# ABE_PRM register map
Vendor: Texas Instruments
Peripheral module from a debugger description file (folder omap4460).
Registers are 32-bit, access not given, reset 0x0 unless marked. A register's access mark holds for its fields unless they carry their own. Offsets are as the file gives them; lines under a group give offsets from that group; [hi:lo] are bit positions; {n}, {i} and the like mark numbered series; 'fields as' and 'values as' point back to an identical list; <NAME> marks a mode.

## ABE_PRM
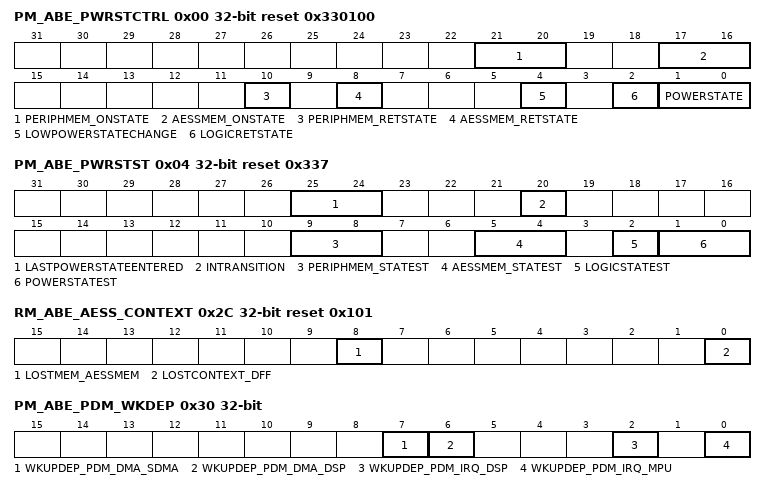
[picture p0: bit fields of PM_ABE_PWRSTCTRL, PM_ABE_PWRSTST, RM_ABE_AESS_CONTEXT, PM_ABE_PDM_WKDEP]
0x00 PM_ABE_PWRSTCTRL reset 0x330100 — This register controls the ABE domain power state to reach upon a domain sleep transition
  [21:20] PERIPHMEM_ONSTATE — PERIPHMEM memory state when domain is ON. (access R Rreturns1s)
    3=PERIPHMEM_ONSTATE_3_r (Memory bank is on when the domain is ON.)
  [17:16] AESSMEM_ONSTATE — AESSMEM memory state when domain is ON. (access R Rreturns1s)
    3=AESSMEM_ONSTATE_3_r (Memory bank is on when the domain is ON.)
  [10] PERIPHMEM_RETSTATE ro — PERIPHMEM memory state when domain is RETENTION.
    0=PERIPHMEM_RETSTATE_0_r (Memory bank is off when the domain is in the RETENTION state.)
  [8] AESSMEM_RETSTATE — AESSMEM memory state when domain is RETENTION. (access R Rreturns1s)
    1=AESSMEM_RETSTATE_1_r (Memory bank is retained when domain is in RETENTION state.)
  [4] LOWPOWERSTATECHANGE — Power state change request when domain has already performed a sleep transition. Allows going into deeper low power state without waking up the power domain. (access RW WSpecial)
    0=Do not request a low power state change; 1=Request a low power state change. This bit is automatically cleared when the power state is effectively changed or when power state is ON.
  [2] LOGICRETSTATE ro — Logic state when power domain is RETENTION
    0=LOGICRETSTATE_0_r (Whole logic is off when the domain is in RETENTION state.)
  [1:0] POWERSTATE rw — Power state control
    0=OFF state; 1=RETENTION state; 2=INACTIVE state; 3=ON State
0x04 PM_ABE_PWRSTST reset 0x337 — This register provides a status on the ABE domain current power domain state. [warm reset insensitive]
  [25:24] LASTPOWERSTATEENTERED — Last low power state entered. Set to 0x3 upon write of the same only. This register is intended for debug purpose only. (access RW W1toSet)
    3=LASTPOWERSTATEENTERED_3_r (Power domain was previously ON-ACTIVE); 2=LASTPOWERSTATEENTERED_2_r (Power domain was previously ON-INACTIVE); 1=LASTPOWERSTATEENTERED_1_r (Power domain was previously in RETENTION); 0=LASTPOWERSTATEENTERED_0_r (Power domain was previously OFF)
  [20] INTRANSITION ro — Domain transition status
    0=INTRANSITION_0_r (No ongoing transition on power domain); 1=INTRANSITION_1_r (Power domain transition is in progress.)
  [9:8] PERIPHMEM_STATEST ro — PERIPHMEM memory state status
    0=PERIPHMEM_STATEST_0_r (Memory is OFF); 1=PERIPHMEM_STATEST_1_r (Reserved); 2=PERIPHMEM_STATEST_2_r (Reserved); 3=PERIPHMEM_STATEST_3_r (Memory is ON)
  [5:4] AESSMEM_STATEST ro — AESSMEM memory state status
    0=AESSMEM_STATEST_0_r (Memory is OFF); 1=AESSMEM_STATEST_1_r (Memory is RETENTION); 2=AESSMEM_STATEST_2_r (Reserved); 3=AESSMEM_STATEST_3_r (Memory is ON)
  [2] LOGICSTATEST ro — Logic state status
    0=LOGICSTATEST_0_r (Logic in domain is OFF); 1=LOGICSTATEST_1_r (Logic in domain is ON)
  [1:0] POWERSTATEST ro — Current power state status
    0=POWERSTATEST_0_r (Power domain is OFF); 1=POWERSTATEST_1_r (Power domain is in RETENTION); 2=POWERSTATEST_2_r (Power domain is ON-INACTIVE); 3=POWERSTATEST_3_r (Power domain is ON-ACTIVE)
0x2C RM_ABE_AESS_CONTEXT reset 0x101 — This register contains dedicated AESS context statuses. [warm reset insensitive]
  [8] LOSTMEM_AESSMEM — Specify if memory-based context in AESSMEM memory bank has been lost due to a previous power transition or other reset source. (access RW W1toClr)
    0=Context has been maintained; 1=Context has been lost
  [0] LOSTCONTEXT_DFF — Specify if DFF-based context has been lost due to a previous power transition or other reset source. (set upon assertion of AUDIO_RST signal) (access RW W1toClr)
    0=Context has been maintained; 1=Context has been lost
0x30 PM_ABE_PDM_WKDEP access per field — This register controls wakeup dependency based on PDM service requests.
  [all] fields
    0=Dependency is disabled; 1=Dependency is enabled
  [7] WKUPDEP_PDM_DMA_SDMA rw — Wakeup dependency from PDM module (softwareakeup_dma signal) towards SDMA + L3_2 + L3_1 domains
  [6] WKUPDEP_PDM_DMA_DSP rw — Wakeup dependency from PDM module (softwareakeup_dma signal) towards DSP domain
  [2] WKUPDEP_PDM_IRQ_DSP rw — Wakeup dependency from PDM module (softwareakeup_irq signal) towards DSP domain
  [0] WKUPDEP_PDM_IRQ_MPU rw — Wakeup dependency from PDM module (softwareakeup_irq signal) towards MPU domain
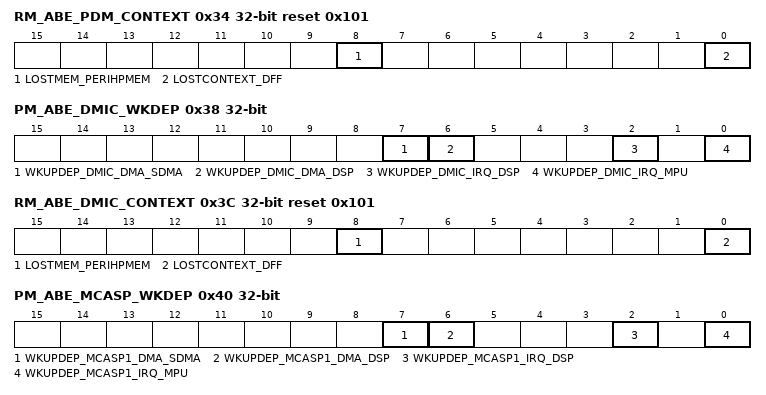
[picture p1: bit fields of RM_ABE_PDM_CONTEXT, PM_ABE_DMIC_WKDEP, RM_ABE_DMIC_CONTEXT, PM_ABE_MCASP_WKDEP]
0x34 RM_ABE_PDM_CONTEXT reset 0x101 — This register contains dedicated PDM context statuses. [warm reset insensitive]
  [8] LOSTMEM_PERIHPMEM — Specify if memory-based context in PERIHPMEM memory bank has been lost due to a previous power transition or other reset source. (access RW W1toClr)
    0=Context has been maintained; 1=Context has been lost
  [0] LOSTCONTEXT_DFF — Specify if DFF-based context has been lost due to a previous power transition or other reset source. (set upon assertion of AUDIO_RST signal) (access RW W1toClr)
    0=Context has been maintained; 1=Context has been lost
0x38 PM_ABE_DMIC_WKDEP access per field — This register controls wakeup dependency based on DMIC service requests.
  [all] fields
    0=Dependency is disabled; 1=Dependency is enabled
  [7] WKUPDEP_DMIC_DMA_SDMA rw — Wakeup dependency from DMIC module (softwareakeup_dma signal) towards SDMA + L3_2 + L3_1 domains
  [6] WKUPDEP_DMIC_DMA_DSP rw — Wakeup dependency from DMIC module (softwareakeup_dma signal) towards DSP domain
  [2] WKUPDEP_DMIC_IRQ_DSP rw — Wakeup dependency from DMIC module (softwareakeup_irq signal) towards DSP domain
  [0] WKUPDEP_DMIC_IRQ_MPU rw — Wakeup dependency from DMIC module (softwareakeup_irq signal) towards MPU domain
0x3C RM_ABE_DMIC_CONTEXT reset 0x101 — This register contains dedicated DMIC context statuses. [warm reset insensitive]
  fields as RM_ABE_PDM_CONTEXT
0x40 PM_ABE_MCASP_WKDEP access per field — This register controls wakeup dependency based on MCASP service requests.
  [all] fields
    0=Dependency is disabled; 1=Dependency is enabled
  [7] WKUPDEP_MCASP1_DMA_SDMA rw — Wakeup dependency from MCASP1 module (softwareakeup_dma signal) towards SDMA + L3_2 + L3_1 domains
  [6] WKUPDEP_MCASP1_DMA_DSP rw — Wakeup dependency from MCASP1 module (softwareakeup_dma signal) towards DSP domain
  [2] WKUPDEP_MCASP1_IRQ_DSP rw — Wakeup dependency from MCASP1 module (softwareakeup_irq signal) towards DSP domain
  [0] WKUPDEP_MCASP1_IRQ_MPU rw — Wakeup dependency from MCASP1 module (softwareakeup_irq signal) towards MPU domain
0x44 RM_ABE_MCASP_CONTEXT reset 0x1 — This register contains dedicated MCASP context statuses. [warm reset insensitive]
  [0] LOSTCONTEXT_DFF — Specify if DFF-based context has been lost due to a previous power transition or other reset source. (set upon assertion of AUDIO_RST signal) (access RW W1toClr)
    0=Context has been maintained; 1=Context has been lost
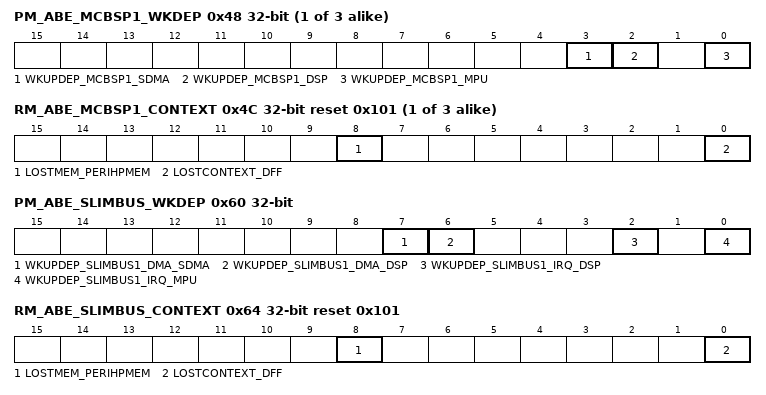
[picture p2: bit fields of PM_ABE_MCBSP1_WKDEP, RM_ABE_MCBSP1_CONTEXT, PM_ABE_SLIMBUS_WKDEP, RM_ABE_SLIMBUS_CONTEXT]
{0x40+8i} PM_ABE_MCBSP{i}_WKDEP access per field (i=1..3) — This register controls wakeup dependency based on MCBSP{i} service requests.
  [all] fields
    0=Dependency is disabled; 1=Dependency is enabled
  [3] WKUPDEP_MCBSP{i}_SDMA rw — Wakeup dependency from MCBSP{i} module (softwareakeup signal) towards SDMA + L3_2 + L3_1 domains
  [2] WKUPDEP_MCBSP{i}_DSP rw — Wakeup dependency from MCBSP{i} module (softwareakeup signal) towards DSP domain
  [0] WKUPDEP_MCBSP{i}_MPU rw — Wakeup dependency from MCBSP{i} module (softwareakeup signal) towards MPU domain
{0x44+8i} RM_ABE_MCBSP{i}_CONTEXT reset 0x101 (i=1..3) — This register contains dedicated MCBSP{i} context statuses. [warm reset insensitive]
  fields as RM_ABE_PDM_CONTEXT
0x60 PM_ABE_SLIMBUS_WKDEP access per field — This register controls wakeup dependency based on SLIMBUS service requests.
  [all] fields
    0=Dependency is disabled; 1=Dependency is enabled
  [7] WKUPDEP_SLIMBUS1_DMA_SDMA rw — Wakeup dependency from SLIMBUS1 module (softwareakeup_dma signal) towards SDMA + L3_2 + L3_1 domains
  [6] WKUPDEP_SLIMBUS1_DMA_DSP rw — Wakeup dependency from SLIMBUS1 module (softwareakeup_dma signal) towards DSP domain
  [2] WKUPDEP_SLIMBUS1_IRQ_DSP rw — Wakeup dependency from SLIMBUS1 module (softwareakeup_irq signal) towards DSP domain
  [0] WKUPDEP_SLIMBUS1_IRQ_MPU rw — Wakeup dependency from SLIMBUS1 module (softwareakeup_irq signal) towards MPU domain
0x64 RM_ABE_SLIMBUS_CONTEXT reset 0x101 — This register contains dedicated SLIMBUS context statuses. [warm reset insensitive]
  fields as RM_ABE_PDM_CONTEXT
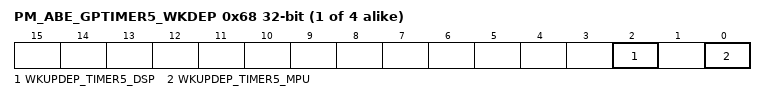
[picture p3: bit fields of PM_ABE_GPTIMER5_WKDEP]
{0x40+8i} PM_ABE_GPTIMER{i}_WKDEP access per field (i=5..8) — This register controls wakeup dependency based on TIMER{i} service requests.
  [2] WKUPDEP_TIMER{i}_DSP rw — Wakeup dependency from TIMER{i} module (softwareakeup signal) towards DSP domain
    0=Dependency is disabled; 1=Dependency is enabled
  [0] WKUPDEP_TIMER{i}_MPU rw — Wakeup dependency from TIMER{i} module (softwareakeup signal) towards MPU domain
    0=Dependency is disabled; 1=Dependency is enabled
{0x44+8i} RM_ABE_GPTIMER{i}_CONTEXT reset 0x1 (i=5..8) — This register contains dedicated TIMER{i} context statuses. [warm reset insensitive]
  fields as RM_ABE_MCASP_CONTEXT
0x88 PM_ABE_WDTIMER3_WKDEP reset 0x1 — This register controls wakeup dependency based on WDT3 service requests.
  [0] WKUPDEP_WDT3_MPU — Wakeup dependency from WDT3 module (softwareakeup signal) towards MPU domain (access R Rreturns1s)
    1=WKUPDEP_WDT3_MPU_1_r (Dependency is enabled)
0x8C RM_ABE_WDTIMER3_CONTEXT reset 0x1 — This register contains dedicated WDT3 context statuses. [warm reset insensitive]
  fields as RM_ABE_MCASP_CONTEXT
